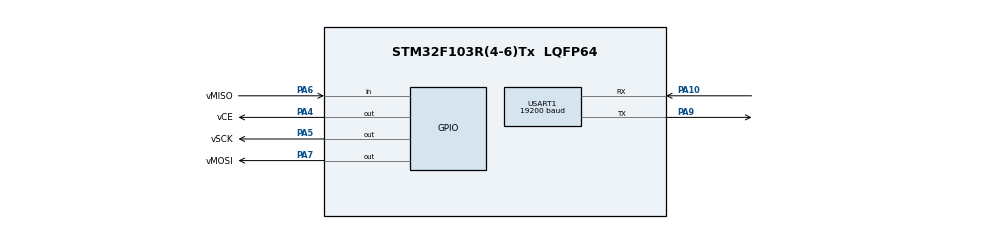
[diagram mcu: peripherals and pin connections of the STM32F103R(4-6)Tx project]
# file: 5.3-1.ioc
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Mcu.Family=STM32F1
Mcu.Name=STM32F103R(4-6)Tx
Mcu.Package=LQFP64
NVIC.PriorityGroup=NVIC_PRIORITYGROUP_4
PA10.Mode=Asynchronous
PA10.Signal=USART1_RX
PA4.GPIO_Label=vCE
PA4.GPIO_PuPd=GPIO_PULLDOWN
PA4.Signal=GPIO_Output
PA5.GPIO_Label=vSCK
PA5.GPIO_ModeDefaultOutputPP=GPIO_MODE_OUTPUT_OD
PA5.GPIO_PuPd=GPIO_PULLUP
PA5.GPIO_Speed=GPIO_SPEED_FREQ_HIGH
PA5.PinState=GPIO_PIN_SET
PA5.Signal=GPIO_Output
PA6.GPIO_Label=vMISO
PA6.GPIO_PuPd=GPIO_PULLUP
PA6.Signal=GPIO_Input
PA7.GPIO_Label=vMOSI
PA7.GPIO_ModeDefaultOutputPP=GPIO_MODE_OUTPUT_OD
PA7.GPIO_PuPd=GPIO_PULLUP
PA7.GPIO_Speed=GPIO_SPEED_FREQ_HIGH
PA7.PinState=GPIO_PIN_SET
PA7.Signal=GPIO_Output
PA9.Mode=Asynchronous
PA9.Signal=USART1_TX
ProjectManager.HeapSize=0x200
ProjectManager.StackSize=0x400
ProjectManager.TargetToolchain=STM32CubeIDE
RCC.APB1Freq_Value=8000000
RCC.APB2Freq_Value=8000000
USART1.BaudRate=19200
USART1.VirtualMode=VM_ASYNC
VP_SYS_VS_ND.Mode=No_Debug
board=custom

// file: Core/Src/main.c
/* USER CODE BEGIN Header */
/**
  ******************************************************************************
  * @file           : main.c
  * @brief          : Main program body
  ******************************************************************************
  * @attention
  *
  * <h2><center>&copy; Copyright (c) 2020 STMicroelectronics.
  * All rights reserved.</center></h2>
  *
  * This software component is licensed by ST under BSD 3-Clause license,
  * the "License"; You may not use this file except in compliance with the
  * License. You may obtain a copy of the License at:
  *                        opensource.org/licenses/BSD-3-Clause
  *
  ******************************************************************************
  */
/* USER CODE END Header */
#include "main.h"

/* USER CODE BEGIN Includes */
#include "stdio.h"
#include "vSPI.h"
#include "TC72.h"
/* USER CODE END Includes */

UART_HandleTypeDef huart1;

void SystemClock_Config(void);
static void MX_GPIO_Init(void);
static void MX_USART1_UART_Init(void);

int main(void)
{
  /* USER CODE BEGIN 1 */
	  float t;
	  char str1[]="Temperature:";
	  char str2[10];
  /* USER CODE END 1 */

  /* MCU Configuration--------------------------------------------------------*/

  /* Reset of all peripherals, Initializes the Flash interface and the Systick. */
  HAL_Init();

  /* Configure the system clock */
  SystemClock_Config();

  /* Initialize all configured peripherals */
  MX_GPIO_Init();
  MX_USART1_UART_Init();

  /* Infinite loop */
  /* USER CODE BEGIN WHILE */
  while (1)
  {
	  HAL_UART_Transmit(&huart1,str1,12,12);
	  TC72_Convert(_TC72_OnceCnv);
	  HAL_Delay(100);
	  t=TC72_TemperatureRd();
	  sprintf(str2,"%f",t);
	  HAL_UART_Transmit(&huart1,str2,7,7);
	  HAL_UART_Transmit(&huart1,&"\n\r",2,2);
	  HAL_Delay(900);
    /* USER CODE END WHILE */

  }
}

void SystemClock_Config(void)
{
  RCC_OscInitTypeDef RCC_OscInitStruct = {0};
  RCC_ClkInitTypeDef RCC_ClkInitStruct = {0};

  /** Initializes the RCC Oscillators according to the specified parameters
  * in the RCC_OscInitTypeDef structure.
  */
  RCC_OscInitStruct.OscillatorType = RCC_OSCILLATORTYPE_HSI;
  RCC_OscInitStruct.HSIState = RCC_HSI_ON;
  RCC_OscInitStruct.HSICalibrationValue = RCC_HSICALIBRATION_DEFAULT;
  RCC_OscInitStruct.PLL.PLLState = RCC_PLL_NONE;
  if (HAL_RCC_OscConfig(&RCC_OscInitStruct) != HAL_OK)
  {
    Error_Handler();
  }
  /** Initializes the CPU, AHB and APB buses clocks
  */
  RCC_ClkInitStruct.ClockType = RCC_CLOCKTYPE_HCLK|RCC_CLOCKTYPE_SYSCLK
                              |RCC_CLOCKTYPE_PCLK1|RCC_CLOCKTYPE_PCLK2;
  RCC_ClkInitStruct.SYSCLKSource = RCC_SYSCLKSOURCE_HSI;
  RCC_ClkInitStruct.AHBCLKDivider = RCC_SYSCLK_DIV1;
  RCC_ClkInitStruct.APB1CLKDivider = RCC_HCLK_DIV1;
  RCC_ClkInitStruct.APB2CLKDivider = RCC_HCLK_DIV1;

  if (HAL_RCC_ClockConfig(&RCC_ClkInitStruct, FLASH_LATENCY_0) != HAL_OK)
  {
    Error_Handler();
  }
}

static void MX_USART1_UART_Init(void)
{

  huart1.Instance = USART1;
  huart1.Init.BaudRate = 19200;
  huart1.Init.WordLength = UART_WORDLENGTH_8B;
  huart1.Init.StopBits = UART_STOPBITS_1;
  huart1.Init.Parity = UART_PARITY_NONE;
  huart1.Init.Mode = UART_MODE_TX_RX;
  huart1.Init.HwFlowCtl = UART_HWCONTROL_NONE;
  huart1.Init.OverSampling = UART_OVERSAMPLING_16;
  if (HAL_UART_Init(&huart1) != HAL_OK)
  {
    Error_Handler();
  }

}

static void MX_GPIO_Init(void)
{
  GPIO_InitTypeDef GPIO_InitStruct = {0};

  /* GPIO Ports Clock Enable */
  __HAL_RCC_GPIOA_CLK_ENABLE();

  /*Configure GPIO pin Output Level */
  HAL_GPIO_WritePin(vCE_GPIO_Port, vCE_Pin, GPIO_PIN_RESET);

  /*Configure GPIO pin Output Level */
  HAL_GPIO_WritePin(GPIOA, vSCK_Pin|vMOSI_Pin, GPIO_PIN_SET);

  /*Configure GPIO pin : vCE_Pin */
  GPIO_InitStruct.Pin = vCE_Pin;
  GPIO_InitStruct.Mode = GPIO_MODE_OUTPUT_PP;
  GPIO_InitStruct.Pull = GPIO_PULLDOWN;
  GPIO_InitStruct.Speed = GPIO_SPEED_FREQ_LOW;
  HAL_GPIO_Init(vCE_GPIO_Port, &GPIO_InitStruct);

  /*Configure GPIO pins : vSCK_Pin vMOSI_Pin */
  GPIO_InitStruct.Pin = vSCK_Pin|vMOSI_Pin;
  GPIO_InitStruct.Mode = GPIO_MODE_OUTPUT_OD;
  GPIO_InitStruct.Pull = GPIO_PULLUP;
  GPIO_InitStruct.Speed = GPIO_SPEED_FREQ_HIGH;
  HAL_GPIO_Init(GPIOA, &GPIO_InitStruct);

  /*Configure GPIO pin : vMISO_Pin */
  GPIO_InitStruct.Pin = vMISO_Pin;
  GPIO_InitStruct.Mode = GPIO_MODE_INPUT;
  GPIO_InitStruct.Pull = GPIO_PULLUP;
  HAL_GPIO_Init(vMISO_GPIO_Port, &GPIO_InitStruct);

}

void Error_Handler(void)
{
}

/************************ (C) COPYRIGHT STMicroelectronics *****END OF FILE****/
